# RZN2H register map
Vendor: Renesas Electronics Corporation; Series: RZN; File version: 1.00.00
CPU: other r0p0, little endian, MPU, no FPU, VTOR, 4 interrupt priority bits, 624 interrupts
Registers are 32-bit, read-write, reset 0x0 unless marked. A register's access mark holds for its fields unless they carry their own. Offsets are from the block's base; [hi:lo] are bit positions; {n}, {i} and the like mark numbered series; 'fields as' and 'values as' point back to an identical list.

## BSC — Bus State Controller
Base 0x80210000
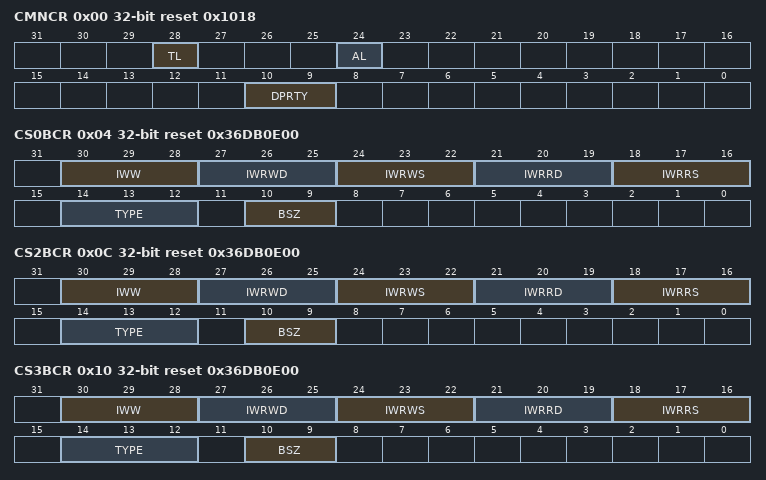
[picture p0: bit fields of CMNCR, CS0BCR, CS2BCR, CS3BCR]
0x00 CMNCR reset 0x1018 — Common Control Register
  [28] TL — Transfer End Level
    0=Active-low output from TEND; 1=Active-high output from TEND
  [24] AL — Acknowledge Level
    0=Active-low output from DACK; 1=Active-high output from DACK
  [10:9] DPRTY — DMA Burst Transfer Priority
    0b0x=Accept a refresh request during DMA burst transfer; 2=Do not accept a refresh request during DMA burst transfer; 3=Setting prohibited
0x04 CS0BCR reset 0x36DB0E00 — CS0 Space Bus Control Register
  [30:28] IWW — Idle Cycles between Write-Read Cycles and Write-Write Cycles
    0=No idle cycle inserted; 1=1 idle cycle inserted; 2=2 idle cycles inserted; 3=4 idle cycles inserted; 4=6 idle cycles inserted; 5=8 idle cycles inserted; 6=10 idle cycles inserted; 7=12 idle cycles inserted
  [27:25] IWRWD — Idle State Insertion between Read-Write Cycles in Different CS Spaces
    values as IWW
  [24:22] IWRWS — Idle State Insertion between Read-Write Cycles in the Same CS Space
    values as IWW
  [21:19] IWRRD — Idle State Insertion between Read-Read Cycles in Different CS Spaces
    values as IWW
  [18:16] IWRRS — Idle State Insertion between Read-Read Cycles in the Same CS Space
    values as IWW
  [14:12] TYPE — Memory Connected to a Space
    0=Normal space; 1=Burst ROM (clock asynchronous); 2=MPX-I/O; 3=SRAM with byte selection; 4=Setting prohibited; 5=Setting prohibited; 6=Setting prohibited; 7=Burst ROM (clock synchronous)
  [10:9] BSZ — Data Bus Width Specification
    0=Setting prohibited; 1=8-bit size; 2=16-bit size; 3=32-bit size
0x0C CS2BCR reset 0x36DB0E00 — CS2 Space Bus Control Register
  fields as CS0BCR
0x10 CS3BCR reset 0x36DB0E00 — CS3 Space Bus Control Register
  fields as CS0BCR
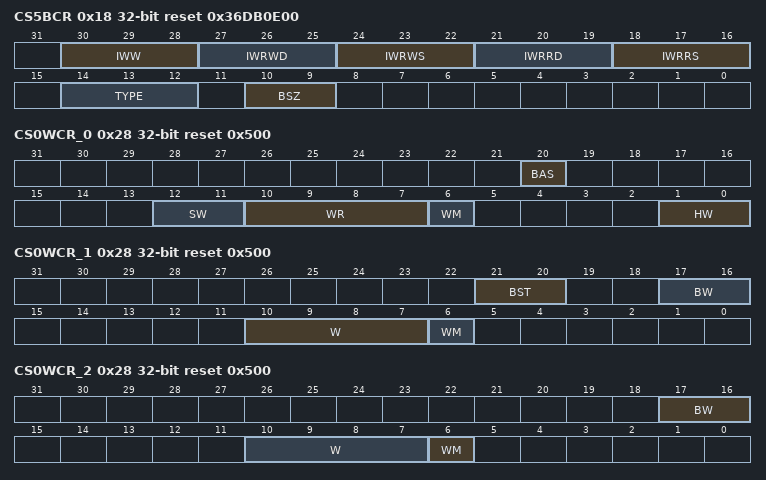
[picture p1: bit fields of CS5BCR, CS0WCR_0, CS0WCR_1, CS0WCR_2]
0x18 CS5BCR reset 0x36DB0E00 — CS5 Space Bus Control Register
  fields as CS0BCR
0x28 CS0WCR_0 reset 0x500 — CS0 Space Wait Control Register for Normal Space, SRAM with Byte Selection
  [20] BAS — SRAM with Byte Selection Byte Access Select
    0=Activates the WEn# signal at the read/write timing and activates the RD/WR# signal during the write access cycle; 1=Activates the WEn# signal during the read/write access cycle and activates the RD/WR# signal at the write timing
  [12:11] SW — Number of Delay Cycles from Address, CSn# Assertion to RD#, WEn# Assertion
    0=0.5 cycles; 1=1.5 cycles; 2=2.5 cycles; 3=3.5 cycles
  [10:7] WR — Number of Access Waits
    0=No wait insertion; 1=1 cycle; {v}={v} cycles (v=2..6); 7=8 cycles; 8=10 cycles; 9=12 cycles; 10=14 cycles; 11=18 cycles; 12=24 cycles; other=Others (Setting prohibited)
  [6] WM — External Wait Mask Specification
    0=External wait input is valid; 1=External wait input is ignored
  [1:0] HW — Delay States from RD#, WEn# Negation to Address, CS0# Negation
    0=0.5 cycles; 1=1.5 cycles; 2=2.5 cycles; 3=3.5 cycles
0x28 CS0WCR_1 reset 0x500 (alternate view of CS0WCR_0) — CS0 Space Wait Control Register for Burst ROM with Clocked Asynchronous
  [21:20] BST — Burst Count Specification
  [17:16] BW — Number of Waits during Burst Access
    0=No wait insertion; 1=1 wait; 2=2 waits; 3=3 waits
  [10:7] W — Number of Access Waits
    0=No wait insertion; 1=1 wait; {v}={v} waits (v=2..6); 7=8 waits; 8=10 waits; 9=12 waits; 10=14 waits; 11=18 waits; 12=24 waits; other=Others (Setting prohibited)
  [6] WM — External Wait Mask Specification
    values as CS0WCR_0.WM
0x28 CS0WCR_2 reset 0x500 (alternate view of CS0WCR_0) — CS0 Space Wait Control Register for Burst ROM with Clocked Synchronous
  [17:16] BW — Number of Burst Wait Cycles
    0=No wait insertion; 1=1 wait; 2=2 waits; 3=3 waits
  [10:7] W — Number of Access Waits
    values as CS0WCR_1.W
  [6] WM — External Wait Mask Specification
    values as CS0WCR_0.WM
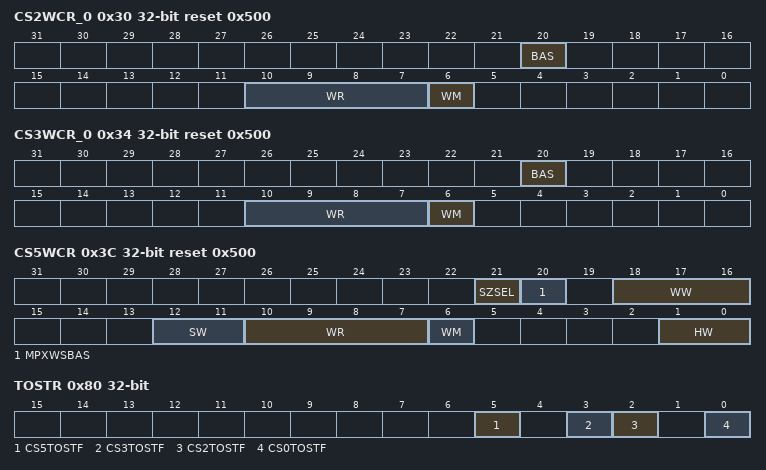
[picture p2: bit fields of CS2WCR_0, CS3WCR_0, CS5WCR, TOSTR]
0x30 CS2WCR_0 reset 0x500 — CS2 Space Wait Control Register for Normal Space, SRAM with Byte Selection
  [20] BAS — SRAM with Byte Selection Byte Access Select
    values as CS0WCR_0.BAS
  [10:7] WR — Number of Access Waits
    values as CS0WCR_0.WR
  [6] WM — External Wait Mask Specification
    values as CS0WCR_0.WM
0x34 CS3WCR_0 reset 0x500 — CS3 Space Wait Control Register for Normal Space, SRAM with Byte Selection
  fields as CS2WCR_0
0x3C CS5WCR reset 0x500 — CS5 Space Wait Control Register for Normal Space, SRAM with Byte Selection, and MPX-I/O
  [21] SZSEL — MPX-I/O Interface Bus Width Specification
  [20] MPXWSBAS — MPX-I/O Interface Address Cycle Wait and SRAM with Byte Selection Byte Access Select
    0=CS5BCR.TYPE[2:0] = 010b: Inserts no wait cycle CS5BCR.TYPE[2:0] = 011b: Activates the WEn# signal at the read/write timing and activates the RD/WR# signal during the write access cycle; 1=CS5BCR.TYPE[2:0] = 010b: Inserts 1 wait cycle CS5BCR.TYPE[2:0] = 011b: Activates the WEn# signal during the read/write access cycle and activates the RD/WR# signal at the write timing
  [18:16] WW — Number of Write Access Waits
    0=The same as WR[3:0] setting (number of read access waits); 1=No wait insertion; 2=1 wait; {v}={v-1} waits (v=3..7)
  [12:11] SW — Number of Delay Cycles from Address, CS5# Assertion to RD#, WEn# Assertion
    0=0.5 states; 1=1.5 states; 2=2.5 states; 3=3.5 states
  [10:7] WR — Number of Read Access Waits
    values as CS0WCR_1.W
  [6] WM — External Wait Mask Specification
    values as CS0WCR_0.WM
  [1:0] HW — Delay Cycles from RD#, WEn# to Address, CS5#
    0=0.5 states; 1=1.5 states; 2=2.5 states; 3=3.5 states
0x60 TOSCOR0 — Timeout Cycle Constant Register 0
  [15:0] TOCNUM — Timeout Cycle Number
0x68 TOSCOR2 — Timeout Cycle Constant Register 2
  [15:0] TOCNUM — Timeout Cycle Number
0x6C TOSCOR3 — Timeout Cycle Constant Register 3
  [15:0] TOCNUM — Timeout Cycle Number
0x74 TOSCOR5 — Timeout Cycle Constant Register 5
  [15:0] TOCNUM — Timeout Cycle Number
0x80 TOSTR — Timeout Status Register
  [5] CS5TOSTF — CS5 Space Timeout Status Flag
  [3] CS3TOSTF — CS3 Space Timeout Status Flag
  [2] CS2TOSTF — CS2 Space Timeout Status Flag
  [0] CS0TOSTF — CS0 Space Timeout Status Flag
    0=Clearing condition When 0 is written in CS0TOSTF; 1=Setting condition When the WM bit in the CS0 space wait control register (CS0WCR) is 0 and the CS0TOEN bit in the timeout enable register (TOENR) is 1, the number of cycles of waiting due to the input on the external wait pin during access to the CS0 space has matched the setting of the TOSCOR0 register
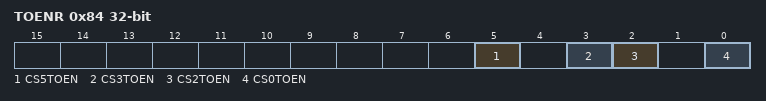
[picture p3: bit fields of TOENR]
0x84 TOENR — Timeout Enable Register
  [all] fields
    0=The timeout detection is disabled; 1=The timeout detection is enabled
  [5] CS5TOEN — CS5 Space Timeout Detection Enable
  [3] CS3TOEN — CS3 Space Timeout Detection Enable
  [2] CS2TOEN — CS2 Space Timeout Detection Enable
  [0] CS0TOEN — CS0 Space Timeout Detection Enable
